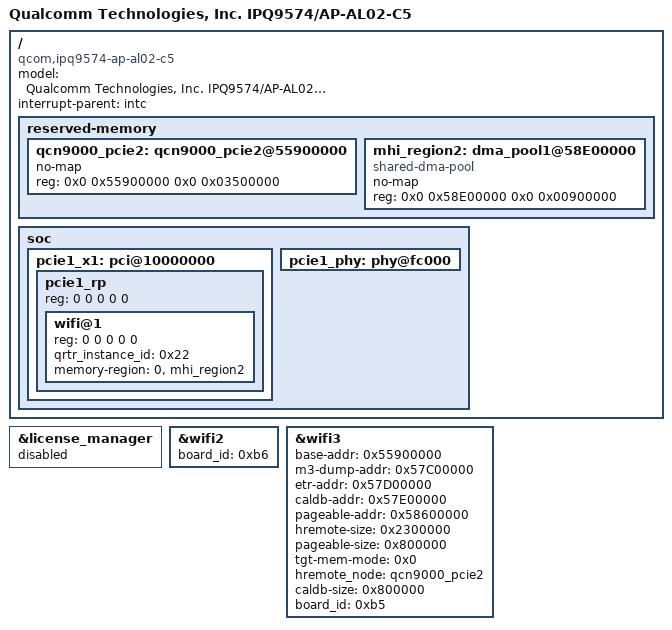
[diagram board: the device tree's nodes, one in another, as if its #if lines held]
// SPDX-License-Identifier: (GPL-2.0+ OR BSD-3-Clause)
/*
 * IPQ9574 AL02-C5 board device tree source
 *
 * Copyright (c) 2020-2021 The Linux Foundation. All rights reserved.
 * Copyright (c) 2022 Qualcomm Innovation Center, Inc. All rights reserved.
 */

/dts-v1/;

#include "ipq9574-al02-c1.dts"

/ {
	#address-cells = <0x2>;
	#size-cells = <0x2>;
	model = "Qualcomm Technologies, Inc. IPQ9574/AP-AL02-C5";
	compatible = "qcom,ipq9574-ap-al02-c5", "qcom,ipq9574-al02", "qcom,ipq9574";
	interrupt-parent = <&intc>;

	/*	Extend Default Profile for third Pine
	 * +=========+==============+========================+
	 * |        |              |                         |
	 * | Region | Start Offset |          Size           |
	 * |        |              |                         |
	 * +--------+--------------+-------------------------+
	 * |        |              |                         |
	 * |  NSS   |  0x40000000  |          32MB           |
	 * |        |              |                         |
	 * +--------+--------------+-------------------------+
	 * |        |              |                         |
	 * |        |              |                         |
	 * |        |              |                         |
	 * |        |              |                         |
	 * | Linux  |  0x42000000  |         123MB           |
	 * |        |              |                         |
	 * |        |              |                         |
	 * |        |              |                         |
	 * +--------+--------------+-------------------------+
	 * |        |              |                         |
	 * |        |              |                         |
	 * | TZ App |  0x49B00000  |           6MB           |
	 * |        |              |                         |
	 * |        |              |                         |
	 * +--------+--------------+-------------------------+
	 * |        |              |                         |
	 * | uboot  |  0x4A100000  |           4MB           |
	 * |        |              |                         |
	 * +--------+--------------+-------------------------+
	 * |  SBL   |  0x4A500000  |           1MB           |
	 * +--------+--------------+-------------------------+
	 * |        |              |                         |
	 * | TZ+HYP |  0x4A600000  |           4MB           |
	 * |        |              |                         |
	 * +--------+--------------+-------------------------+
	 * |  smem  |  0x4AA00000  |           1MB           |
	 * +--------+--------------+-------------------------+
	 * |        |              |                         |
	 * |        |              |                         |
	 * | WLAN   |              |                         |
	 * |   Q6   |  0x4AB00000  |          43MB           |
	 * |        |              |                         |
	 * |        |              |                         |
	 * +--------+--------------+-------------------------+
	 * | M3 Dump|  0x4D600000  |           1MB           |
	 * +--------+--------------+-------------------------+
	 * | WLAN   |              |                         |
	 * | Q6 ETR |  0x4D700000  |           1MB           |
	 * | Region |              |                         |
	 * +--------+--------------+-------------------------+
	 * | caldb  |  0x4D800000  |           5MB           |
	 * +--------+--------------+-------------------------+
	 * |        |              |                         |
	 * |  Pine0 |  0x4DD00000  |          53MB           |
	 * |        |              |                         |
	 * +--------+--------------+-------------------------+
	 * |        |              |                         |
	 * |  Pine1 |  0x51200000  |          53MB           |
	 * |        |              |                         |
	 * +--------+--------------+-------------------------+
	 * |        |              |                         |
	 * |  MHI0  |  0x54700000  |           9MB           |
	 * |        |              |                         |
	 * +--------+--------------+-------------------------+
	 * |        |              |                         |
	 * |  MHI1  |  0x55000000  |           9MB           |
	 * |        |              |                         |
	 * +--------+--------------+-------------------------+
	 * |        |              |                         |
	 * |  Pine2 |  0x55900000  |          53MB           |
	 * |        |              |                         |
	 * +--------+--------------+-------------------------+
	 * |        |              |                         |
	 * |  MHI2  |  0x58E00000  |           9MB           |
	 * |        |              |                         |
	 * +=================================================+
	 * |                                                 |
	 * |                                                 |
	 * |                                                 |
	 * |            Rest of memory for Linux             |
	 * |                                                 |
	 * |                                                 |
	 * |                                                 |
	 * +=================================================+
	 */
	reserved-memory {
		qcn9000_pcie2: qcn9000_pcie2@55900000 {
			no-map;
			reg = <0x0 0x55900000 0x0 0x03500000>;
		};
		mhi_region2: dma_pool1@58E00000 {
			compatible = "shared-dma-pool";
			no-map;
			reg = <0x0 0x58E00000 0x0 0x00900000>;
		};
	};

	soc {
		pcie1_x1: pci@10000000 {
			status = "ok";
			pcie1_rp {
				reg = <0 0 0 0 0>;

				wifi@1 {
					reg = <0 0 0 0 0>;
					qrtr_instance_id = <0x22>;
#if defined(__CNSS2__)
					memory-region = <0>,<&mhi_region2>;
#endif
					status = "ok";
				};
			};
		};

		pcie1_phy: phy@fc000 {
			status = "ok";
		};
	};
};

&license_manager {
	status = "disabled";
};

&wifi2 {
	board_id = <0xb6>;
};

&wifi3 {
#if !defined(__IPQ_MEM_PROFILE_256_MB__) && !defined(__IPQ_MEM_PROFILE_512_MB__)
	/* QCN9000 tgt-mem-mode=0 layout - 53MB
	 * +=========+==============+=========+
	 * |  Region | Start Offset |   Size  |
	 * +---------+--------------+---------+
	 * | HREMOTE |  0x55900000  |   35MB  |
	 * +---------+--------------+---------+
	 * | M3 Dump |  0x57C00000  |   1MB   |
	 * +---------+--------------+---------+
	 * |   ETR   |  0x57D00000  |   1MB   |
	 * +---------+--------------+---------+
	 * |  Caldb  |  0x57E00000  |   8MB   |
	 * +---------+--------------+---------+
	 * | Pageable|  0x58600000  |   8MB   |
	 * +==================================+
	 */
	base-addr = <0x55900000>;
	m3-dump-addr = <0x57C00000>;
	etr-addr = <0x57D00000>;
	caldb-addr = <0x57E00000>;
	pageable-addr = <0x58600000>;
	hremote-size = <0x2300000>;
	pageable-size = <0x800000>;
	tgt-mem-mode = <0x0>;
	hremote_node = <&qcn9000_pcie2>;
	caldb-size = <0x800000>;
	board_id = <0xb5>;
	status = "ok";
#endif
};
